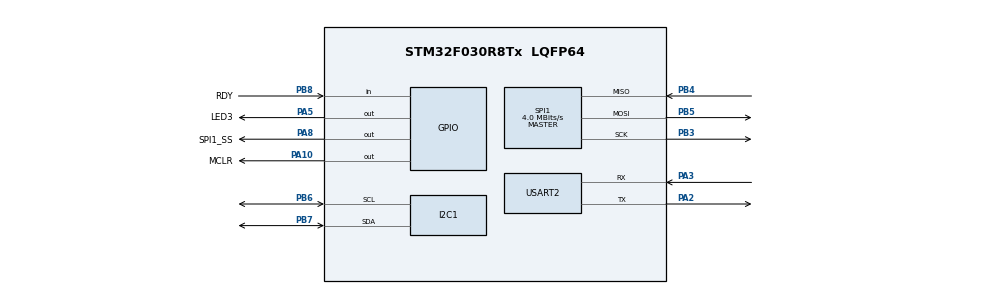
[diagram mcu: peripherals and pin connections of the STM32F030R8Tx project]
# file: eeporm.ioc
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Mcu.Family=STM32F0
Mcu.Name=STM32F030R8Tx
Mcu.Package=LQFP64
PA10.GPIO_Label=MCLR
PA10.Signal=GPIO_Output
PA2.Mode=Asynchronous
PA2.Signal=USART2_TX
PA3.Mode=Asynchronous
PA3.Signal=USART2_RX
PA5.GPIO_Label=LED3
PA5.Signal=GPIO_Output
PA8.GPIO_Label=SPI1_SS
PA8.Signal=GPIO_Output
PB3.Mode=Full_Duplex_Master
PB3.Signal=SPI1_SCK
PB4.Mode=Full_Duplex_Master
PB4.Signal=SPI1_MISO
PB5.Mode=Full_Duplex_Master
PB5.Signal=SPI1_MOSI
PB6.Mode=I2C
PB6.Signal=I2C1_SCL
PB7.Mode=I2C
PB7.Signal=I2C1_SDA
PB8.GPIO_Label=RDY
PB8.Signal=GPIO_Input
ProjectManager.HeapSize=0x200
ProjectManager.StackSize=0x400
ProjectManager.TargetToolchain=MDK-ARM V5
SPI1.CalculateBaudRate=4.0 MBits/s
SPI1.Direction=SPI_DIRECTION_2LINES
SPI1.Mode=SPI_MODE_MASTER
SPI1.VirtualType=VM_MASTER
USART2.VirtualMode-Asynchronous=VM_ASYNC
board=eeporm

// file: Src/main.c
/**
  ******************************************************************************
  * File Name          : main.c
  * Description        : Main program body
  ******************************************************************************
  ** This notice applies to any and all portions of this file
  * that are not between comment pairs USER CODE BEGIN and
  * USER CODE END. Other portions of this file, whether
  * inserted by the user or by software development tools
  * are owned by their respective copyright owners.
  *
  * COPYRIGHT(c) 2017 STMicroelectronics
  *
  * Redistribution and use in source and binary forms, with or without modification,
  * are permitted provided that the following conditions are met:
  *   1. Redistributions of source code must retain the above copyright notice,
  *      this list of conditions and the following disclaimer.
  *   2. Redistributions in binary form must reproduce the above copyright notice,
  *      this list of conditions and the following disclaimer in the documentation
  *      and/or other materials provided with the distribution.
  *   3. Neither the name of STMicroelectronics nor the names of its contributors
  *      may be used to endorse or promote products derived from this software
  *      without specific prior written permission.
  *
  * THIS SOFTWARE IS PROVIDED BY THE COPYRIGHT HOLDERS AND CONTRIBUTORS "AS IS"
  * AND ANY EXPRESS OR IMPLIED WARRANTIES, INCLUDING, BUT NOT LIMITED TO, THE
  * IMPLIED WARRANTIES OF MERCHANTABILITY AND FITNESS FOR A PARTICULAR PURPOSE ARE
  * DISCLAIMED. IN NO EVENT SHALL THE COPYRIGHT HOLDER OR CONTRIBUTORS BE LIABLE
  * FOR ANY DIRECT, INDIRECT, INCIDENTAL, SPECIAL, EXEMPLARY, OR CONSEQUENTIAL
  * DAMAGES (INCLUDING, BUT NOT LIMITED TO, PROCUREMENT OF SUBSTITUTE GOODS OR
  * SERVICES; LOSS OF USE, DATA, OR PROFITS; OR BUSINESS INTERRUPTION) HOWEVER
  * CAUSED AND ON ANY THEORY OF LIABILITY, WHETHER IN CONTRACT, STRICT LIABILITY,
  * OR TORT (INCLUDING NEGLIGENCE OR OTHERWISE) ARISING IN ANY WAY OUT OF THE USE
  * OF THIS SOFTWARE, EVEN IF ADVISED OF THE POSSIBILITY OF SUCH DAMAGE.
  *
  ******************************************************************************
  */
#include "stm32f0xx_hal.h"
#include "hwcfg.h"
#include "iqs316_driver.h"
uint8_t GROUP,PROX,TOUCH,TouchStatus[5];
int main(void)
{

  HAL_Init();
  SystemClock_Config();

  MX_GPIO_Init();
  MX_I2C1_Init();
  MX_SPI1_Init();
  MX_USART2_UART_Init();

  /* USER CODE BEGIN 2 */
  printf("\n\r Init is OK !\n\r");
	printf("\n\r IQS316 Seeting Start !\n\r");
  /* USER CODE END 2 */
  /* Infinite loop */
  /* USER CODE BEGIN WHILE */
	IQS316_Init();
	HAL_GPIO_WritePin(LED3_GPIO_Port, LED3_Pin,GPIO_PIN_SET);
  /* USER CODE END WHILE */

  while (1)
  {
   IQS316_Refresh_Data();
   IQS316_Process_Data();
  }
}

void _Error_Handler(char * file, int line)
{
  while(1)
  {
  }
}

/************************ (C) COPYRIGHT STMicroelectronics *****END OF FILE****/
